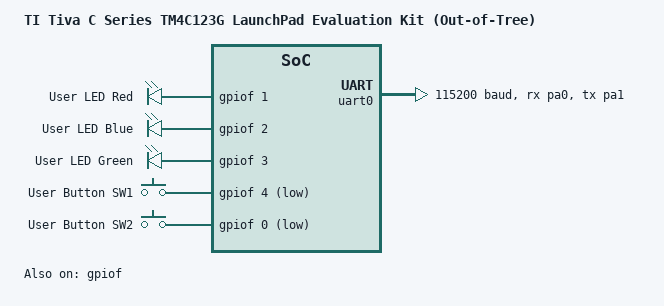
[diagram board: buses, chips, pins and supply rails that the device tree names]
/*
 * SPDX-License-Identifier: Apache-2.0
 *
 * TI Tiva C Series TM4C123G LaunchPad (EK-TM4C123GXL)
 * Out-of-tree board definition
 */

/dts-v1/;

#include <ti/tm4c123gh6pm.dtsi>
#include <dt-bindings/pinctrl/tiva-c-pinctrl.h>
#include <zephyr/dt-bindings/gpio/gpio.h>

/*
 * Pin configuration node for UART0.
 * Encoded with TIVA_C_PINMUX(port, pin, mux, type).
 */
&pinctrl {
	uart0_rx_pa0: uart0_rx_pa0 {
		pinmux = <TIVA_C_PINMUX(TIVA_C_PORT_A, 0, 1, TIVA_C_TYPE_UART)>;
	};

	uart0_tx_pa1: uart0_tx_pa1 {
		pinmux = <TIVA_C_PINMUX(TIVA_C_PORT_A, 1, 1, TIVA_C_TYPE_UART)>;
	};
};

/ {
	compatible = "ti,ek-tm4c123gxl", "ti,tm4c123gh6pm";
	model = "TI Tiva C Series TM4C123G LaunchPad Evaluation Kit (Out-of-Tree)";

	chosen {
		zephyr,sram = &sram0;
		zephyr,flash = &flash0;
		zephyr,console = &uart0;
		zephyr,shell-uart = &uart0;
	};

	leds {
		compatible = "gpio-leds";
		led_red: led_0 {
			gpios = <&gpiof 1 GPIO_ACTIVE_HIGH>;
			label = "User LED Red";
		};
		led_blue: led_1 {
			gpios = <&gpiof 2 GPIO_ACTIVE_HIGH>;
			label = "User LED Blue";
		};
		led_green: led_2 {
			gpios = <&gpiof 3 GPIO_ACTIVE_HIGH>;
			label = "User LED Green";
		};
	};

	buttons {
		compatible = "gpio-keys";
		btn_sw1: button_0 {
			gpios = <&gpiof 4 (GPIO_PULL_UP | GPIO_ACTIVE_LOW)>;
			label = "User Button SW1";
		};
		btn_sw2: button_1 {
			gpios = <&gpiof 0 (GPIO_PULL_UP | GPIO_ACTIVE_LOW)>;
			label = "User Button SW2";
		};
	};

	aliases {
		uart-0 = &uart0;
		led0 = &led_red;
		led1 = &led_blue;
		led2 = &led_green;
		sw0 = &btn_sw1;
		sw1 = &btn_sw2;
	};

	soc {
		gpiof: gpio@40025000 {
			compatible = "ti,tiva-c-gpio";
			reg = <0x40025000 0x1000>;
			interrupts = <30 3>;
			gpio-controller;
			#gpio-cells = <2>;
			ngpios = <5>;
			status = "okay";
		};
	};
};

/* UART0 is connected to the on-board ICDI virtual COM port (PA0/PA1) */
&uart0 {
	current-speed = <115200>;
	pinctrl-0 = <&uart0_rx_pa0 &uart0_tx_pa1>;
	pinctrl-names = "default";
	status = "okay";
};
